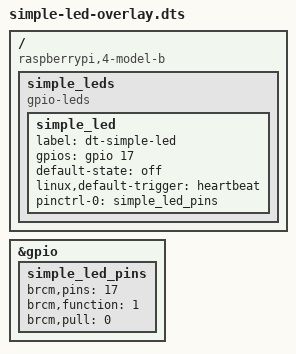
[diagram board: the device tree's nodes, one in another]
/dts-v1/;
/plugin/;

/ {
    compatible = "raspberrypi,4-model-b";

    fragment@0 {
        target = <&gpio>;
        __overlay__ {
            simple_led_pins: simple_led_pins {
                brcm,pins = <17>;
                brcm,function = <1>; /* output */
                brcm,pull = <0>;     /* none */
            };
        };
    };

    fragment@1 {
        target-path = "/";
        __overlay__ {
            simple_leds: simple_leds {
                compatible = "gpio-leds";

                simple_led {
                    label = "dt-simple-led";
                    gpios = <&gpio 17 0>;
                    default-state = "off";
                    linux,default-trigger = "heartbeat";
                    pinctrl-names = "default";
                    pinctrl-0 = <&simple_led_pins>;
                };
            };
        };
    };
};
